VERSION "HIPBNYYYYYYYYYYYYYYYYYYYYYYYYYYYYYYYYYYYYY/4/%%%/4/'%**4YYY///"

NS_ :

BS_:

BU_: EW_CAN0

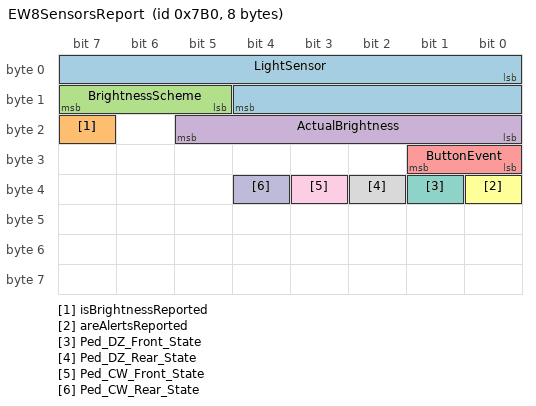
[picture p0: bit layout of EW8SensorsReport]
BO_ 1968 EW8SensorsReport: 8 EW_CAN0
 SG_ LightSensor : 0|13@1+ (1,0) [0|8191] "mV" Vector__XXX
 SG_ isBrightnessReported : 23|1@1+ (1,0) [0|1] "" Vector__XXX
 SG_ BrightnessScheme : 13|3@1+ (1,0) [0|7] "level" Vector__XXX
 SG_ ActualBrightness : 16|6@1+ (1,0) [0|41] "level" Vector__XXX
 SG_ ButtonEvent : 24|2@1+ (1,0) [0|0] "" Vector__XXX
 SG_ areAlertsReported : 32|1@1+ (1,0) [0|0] "" Vector__XXX
 SG_ Ped_DZ_Front_State : 33|1@1+ (1,0) [0|0] "" Vector__XXX
 SG_ Ped_DZ_Rear_State : 34|1@1+ (1,0) [0|0] "" Vector__XXX
 SG_ Ped_CW_Front_State : 35|1@1+ (1,0) [0|0] "" Vector__XXX
 SG_ Ped_CW_Rear_State : 36|1@1+ (1,0) [0|0] "" Vector__XXX

VAL_ 1968 isBrightnessReported 0 "off" 1 "on" ;
VAL_ 1968 ButtonEvent 0 "isNotReported" 1 "down" 2 "enter" 3 "up" ;
